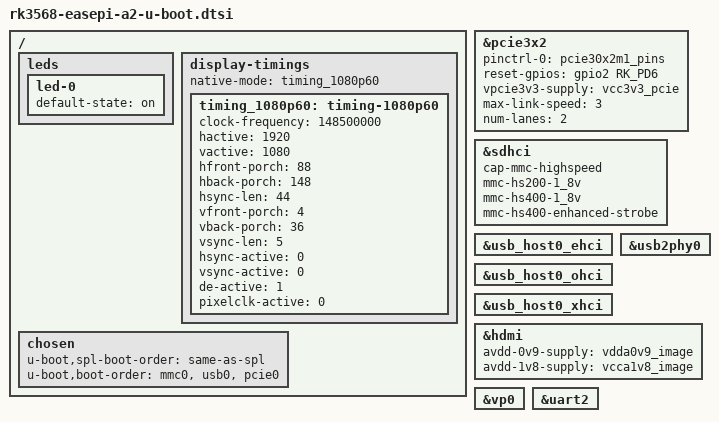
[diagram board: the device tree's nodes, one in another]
// SPDX-License-Identifier: GPL-2.0+
/*
 * (C) Copyright 2021 Rockchip Electronics Co., Ltd
 * (C) Copyright 2023 Akash Gajjar <gajjar04akash@gmail.com>
 * (C) Copyright 2026 EasePi-A2
 */

#include "rk356x-u-boot.dtsi"

/ {
	leds {
		led-0 {
			default-state = "on";
		};
	};

	/* HDMI configuration for U-Boot second stage output */
	display-timings {
		native-mode = <&timing_1080p60>;

		timing_1080p60: timing-1080p60 {
			clock-frequency = <148500000>;
			hactive = <1920>;
			vactive = <1080>;
			hfront-porch = <88>;
			hback-porch = <148>;
			hsync-len = <44>;
			vfront-porch = <4>;
			vback-porch = <36>;
			vsync-len = <5>;
			hsync-active = <0>;
			vsync-active = <0>;
			de-active = <1>;
			pixelclk-active = <0>;
		};
	};

	/* Boot order configuration */
	chosen {
		u-boot,spl-boot-order = "same-as-spl", &sdhci, &usb_host0_xhci, &pcie3x2;
		u-boot,boot-order = "mmc0", "usb0", "pcie0";
	};
};

/* PCIe NVMe support - consistent with main device tree */
&pcie3x2 {
	pinctrl-names = "default";
	pinctrl-0 = <&pcie30x2m1_pins>;
	reset-gpios = <&gpio2 RK_PD6 GPIO_ACTIVE_HIGH>;
	vpcie3v3-supply = <&vcc3v3_pcie>;
	max-link-speed = <3>;
	num-lanes = <2>;
	status = "okay";
};

/* eMMC boot support */
&sdhci {
	cap-mmc-highspeed;
	mmc-hs200-1_8v;
	mmc-hs400-1_8v;
	mmc-hs400-enhanced-strobe;
	bootph-pre-ram;
	bootph-some-ram;
	status = "okay";
};

/* USB boot support */
&usb_host0_ehci {
	status = "okay";
};

&usb_host0_ohci {
	status = "okay";
};

&usb_host0_xhci {
	status = "okay";
};

&usb2phy0 {
	status = "okay";
};

/* HDMI controller configuration for U-Boot second stage */
&hdmi {
	avdd-0v9-supply = <&vdda0v9_image>;
	avdd-1v8-supply = <&vcca1v8_image>;
	status = "okay";
};

/* Ensure VP0 display pipeline enabled in U-Boot stage */
&vp0 {
	status = "okay";
};

/* Enable U-Boot boot menu */
&uart2 {
	status = "okay";
};
